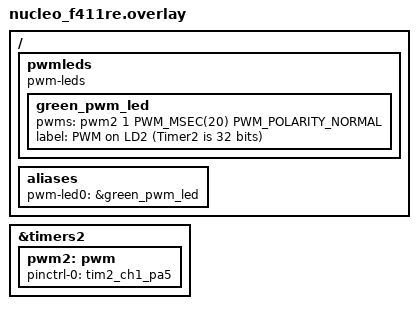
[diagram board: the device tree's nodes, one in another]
/*
 * SPDX-License-Identifier: Apache-2.0
 *
 * Copyright (c) 2024 Technaid SL
 */

/ {
	pwmleds: pwmleds {
		compatible = "pwm-leds";
		status = "okay";

		green_pwm_led: green_pwm_led {
			pwms = <&pwm2 1 PWM_MSEC(20) PWM_POLARITY_NORMAL>;
			label = "PWM on LD2 (Timer2 is 32 bits)";
		};
	};

	aliases {
		pwm-led0 = &green_pwm_led;
	};

};

&timers2 {
    status = "okay";

    pwm2: pwm {
        status = "okay";
        pinctrl-0 = <&tim2_ch1_pa5>;
        pinctrl-names = "default";
    };
};
